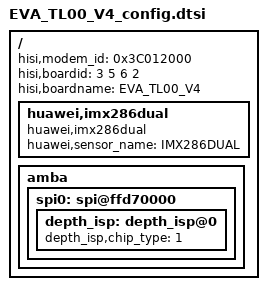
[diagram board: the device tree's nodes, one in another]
/**
 * Huawei Ltd.
 * PhosphorV660
 */


/include/ "EVA_TUGL_V1_config.dtsi"

/{
	hisi,modem_id = <0x3C012000>;
	hisi,boardid = <3 5 6 2>;
	hisi,boardname = "EVA_TL00_V4";
	huawei,imx286dual{
		compatible = "huawei,imx286dual";
		huawei,sensor_name = "IMX286DUAL";
	};
	amba{
		spi0: spi@ffd70000{
			depth_isp: depth_isp@0 {
				/*chip-type 1:dummy  2:Al6045  4:Al6610*/
				depth_isp,chip_type = <1>;
			};
		};
	};
};
